# CC1350F128 register map
File version: 1.0
CPU: CM3 1.0, other endian, MPU, FPU, 3 interrupt priority bits
Registers are 32-bit, read-write, reset 0x0 unless marked. A register's access mark holds for its fields unless they carry their own. Offsets are from the block's base; [hi:lo] are bit positions; {n}, {i} and the like mark numbered series; 'fields as' and 'values as' point back to an identical list.

## FCFG1 — Factory configuration area (FCFG1)
Base 0x50001000
0xA0 MISC_CONF_1 reset 0xFFFFFF00 — Misc configurations
  [7:0] DEVICE_MINOR_REV ro — [7:0] HW minor revision number (a value of 0xFF shall be treated equally to 0x00). Any test of this field by SW should be implemented as a 'greater or equal' comparison as signed integer. Value may change without warning.
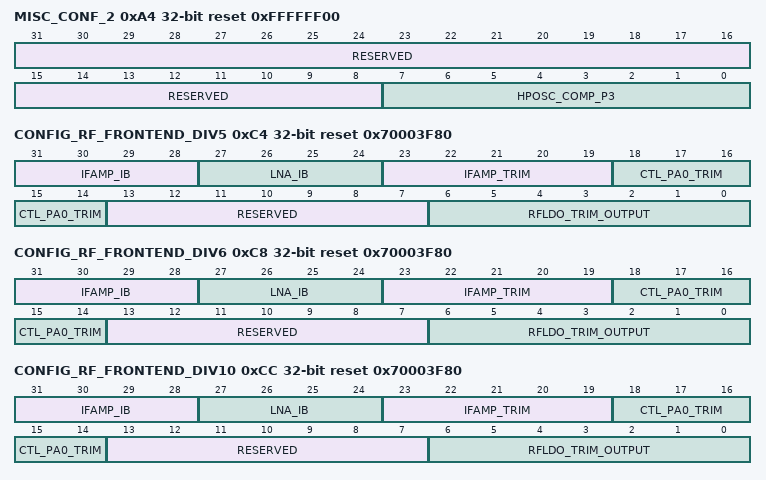
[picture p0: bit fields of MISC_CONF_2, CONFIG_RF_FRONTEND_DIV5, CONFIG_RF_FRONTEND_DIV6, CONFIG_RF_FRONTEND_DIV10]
0xA4 MISC_CONF_2 reset 0xFFFFFF00 — Internal. Only to be used through TI provided API.
  [31:8] RESERVED ro — [31:8] Internal. Only to be used through TI provided API.
  [7:0] HPOSC_COMP_P3 ro — [7:0] Internal. Only to be used through TI provided API.
0xC4 CONFIG_RF_FRONTEND_DIV5 reset 0x70003F80 — Internal. Only to be used through TI provided API.
  [31:28] IFAMP_IB ro — [31:28] Internal. Only to be used through TI provided API.
  [27:24] LNA_IB ro — [27:24] Internal. Only to be used through TI provided API.
  [23:19] IFAMP_TRIM ro — [23:19] Internal. Only to be used through TI provided API.
  [18:14] CTL_PA0_TRIM ro — [18:14] Internal. Only to be used through TI provided API.
  [13:7] RESERVED ro — [13:7] Internal. Only to be used through TI provided API.
  [6:0] RFLDO_TRIM_OUTPUT ro — [6:0] Internal. Only to be used through TI provided API.
0xC8 CONFIG_RF_FRONTEND_DIV6 reset 0x70003F80 — Internal. Only to be used through TI provided API.
  fields as CONFIG_RF_FRONTEND_DIV5
0xCC CONFIG_RF_FRONTEND_DIV10 reset 0x70003F80 — Internal. Only to be used through TI provided API.
  fields as CONFIG_RF_FRONTEND_DIV5
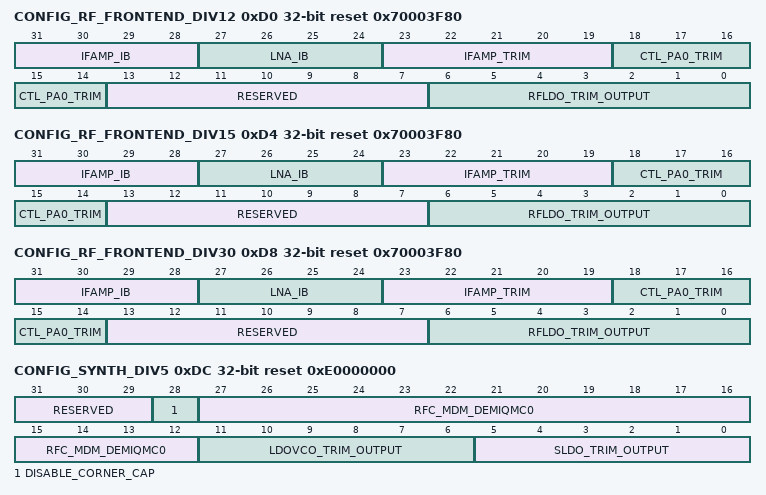
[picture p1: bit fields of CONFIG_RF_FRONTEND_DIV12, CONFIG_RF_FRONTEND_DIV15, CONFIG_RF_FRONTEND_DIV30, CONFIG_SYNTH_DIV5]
0xD0 CONFIG_RF_FRONTEND_DIV12 reset 0x70003F80 — Internal. Only to be used through TI provided API.
  fields as CONFIG_RF_FRONTEND_DIV5
0xD4 CONFIG_RF_FRONTEND_DIV15 reset 0x70003F80 — Internal. Only to be used through TI provided API.
  fields as CONFIG_RF_FRONTEND_DIV5
0xD8 CONFIG_RF_FRONTEND_DIV30 reset 0x70003F80 — Internal. Only to be used through TI provided API.
  fields as CONFIG_RF_FRONTEND_DIV5
0xDC CONFIG_SYNTH_DIV5 reset 0xE0000000 — Internal. Only to be used through TI provided API.
  [31:29] RESERVED ro — [31:29] Internal. Only to be used through TI provided API.
  [28] DISABLE_CORNER_CAP ro — [28:28] Internal. Only to be used through TI provided API.
  [27:12] RFC_MDM_DEMIQMC0 ro — [27:12] Trim value for RF Core. Value is read by RF Core ROM FW during RF Core initialization.
  [11:6] LDOVCO_TRIM_OUTPUT ro — [11:6] Internal. Only to be used through TI provided API.
  [5:0] SLDO_TRIM_OUTPUT ro — [5:0] Internal. Only to be used through TI provided API.
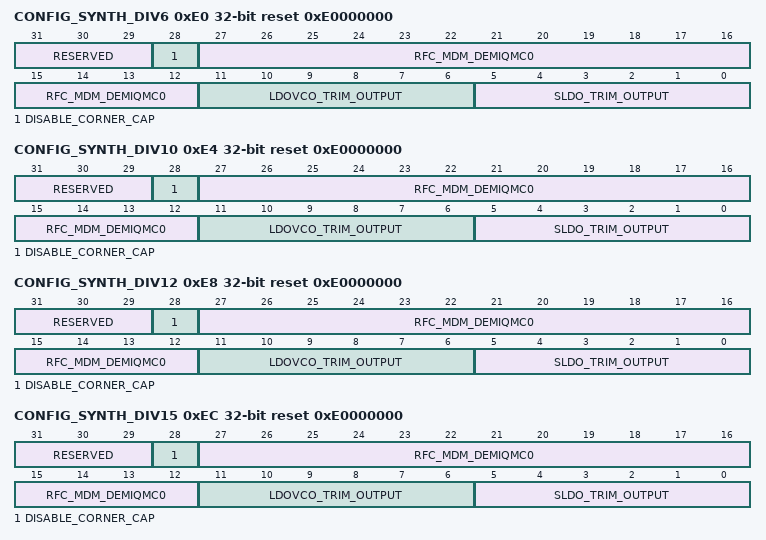
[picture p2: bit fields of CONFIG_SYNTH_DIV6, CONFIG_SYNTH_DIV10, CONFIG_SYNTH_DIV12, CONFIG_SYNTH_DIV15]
0xE0 CONFIG_SYNTH_DIV6 reset 0xE0000000 — Internal. Only to be used through TI provided API.
  fields as CONFIG_SYNTH_DIV5
0xE4 CONFIG_SYNTH_DIV10 reset 0xE0000000 — Internal. Only to be used through TI provided API.
  fields as CONFIG_SYNTH_DIV5
0xE8 CONFIG_SYNTH_DIV12 reset 0xE0000000 — Internal. Only to be used through TI provided API.
  fields as CONFIG_SYNTH_DIV5
0xEC CONFIG_SYNTH_DIV15 reset 0xE0000000 — Internal. Only to be used through TI provided API.
  fields as CONFIG_SYNTH_DIV5
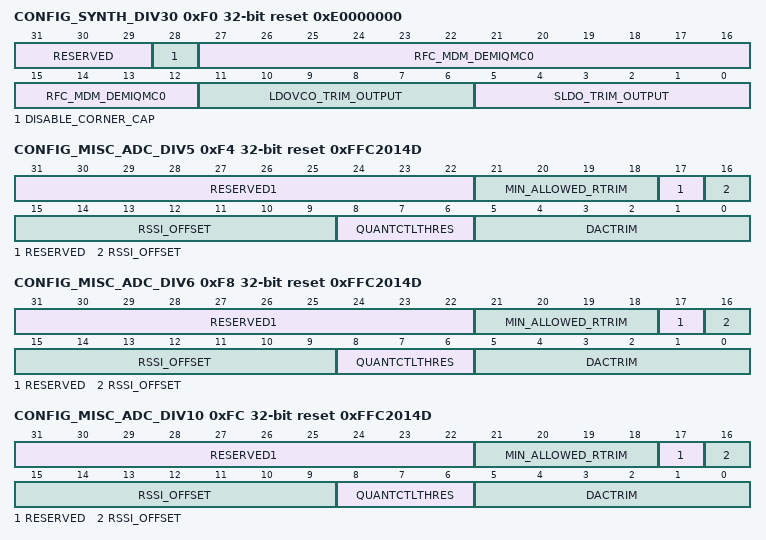
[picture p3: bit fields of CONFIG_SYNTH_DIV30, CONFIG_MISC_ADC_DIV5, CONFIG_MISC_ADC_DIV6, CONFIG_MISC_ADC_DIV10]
0xF0 CONFIG_SYNTH_DIV30 reset 0xE0000000 — Internal. Only to be used through TI provided API.
  fields as CONFIG_SYNTH_DIV5
0xF4 CONFIG_MISC_ADC_DIV5 reset 0xFFC2014D — Internal. Only to be used through TI provided API.
  [31:22] RESERVED1 ro — [31:22] Internal. Only to be used through TI provided API.
  [21:18] MIN_ALLOWED_RTRIM ro — [21:18] Internal. Only to be used through TI provided API.
  [17] RESERVED ro — [17:17] Internal. Only to be used through TI provided API.
  [16:9] RSSI_OFFSET ro — [16:9] Internal. Only to be used through TI provided API.
  [8:6] QUANTCTLTHRES ro — [8:6] Internal. Only to be used through TI provided API.
  [5:0] DACTRIM ro — [5:0] Internal. Only to be used through TI provided API.
0xF8 CONFIG_MISC_ADC_DIV6 reset 0xFFC2014D — Internal. Only to be used through TI provided API.
  fields as CONFIG_MISC_ADC_DIV5
0xFC CONFIG_MISC_ADC_DIV10 reset 0xFFC2014D — Internal. Only to be used through TI provided API.
  fields as CONFIG_MISC_ADC_DIV5
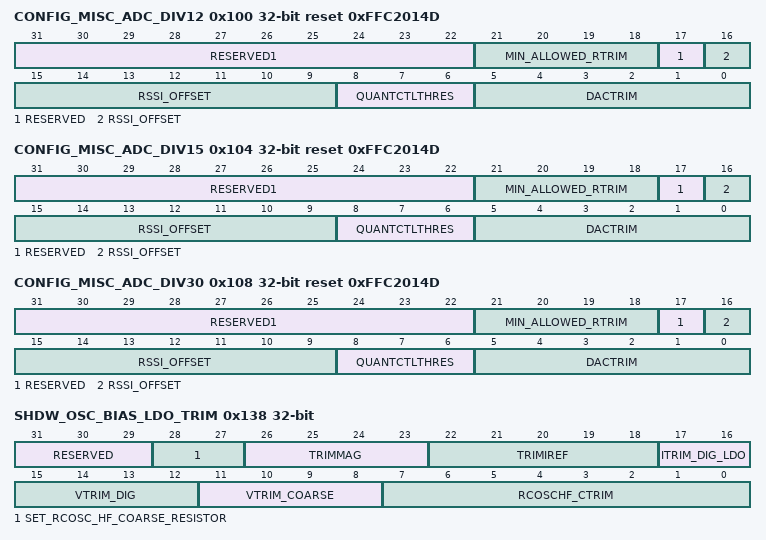
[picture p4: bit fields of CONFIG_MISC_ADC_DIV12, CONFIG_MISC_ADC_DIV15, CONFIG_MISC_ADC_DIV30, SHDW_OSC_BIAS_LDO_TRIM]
0x100 CONFIG_MISC_ADC_DIV12 reset 0xFFC2014D — Internal. Only to be used through TI provided API.
  fields as CONFIG_MISC_ADC_DIV5
0x104 CONFIG_MISC_ADC_DIV15 reset 0xFFC2014D — Internal. Only to be used through TI provided API.
  fields as CONFIG_MISC_ADC_DIV5
0x108 CONFIG_MISC_ADC_DIV30 reset 0xFFC2014D — Internal. Only to be used through TI provided API.
  fields as CONFIG_MISC_ADC_DIV5
{0x118+4i} SHDW_DIE_ID_{i} (i=0..3) — Shadow of the DIE_ID_{i} register in eFuse
  [31:0] ID_{32i+31}_{32i} ro — [31:0] Shadow of the DIE_ID_{i} register in eFuse row number {i+3}
0x138 SHDW_OSC_BIAS_LDO_TRIM — Internal. Only to be used through TI provided API.
  [31:29] RESERVED ro — [31:29] Internal. Only to be used through TI provided API.
  [28:27] SET_RCOSC_HF_COARSE_RESISTOR ro — [28:27] Internal. Only to be used through TI provided API.
  [26:23] TRIMMAG ro — [26:23] Internal. Only to be used through TI provided API.
  [22:18] TRIMIREF ro — [22:18] Internal. Only to be used through TI provided API.
  [17:16] ITRIM_DIG_LDO ro — [17:16] Internal. Only to be used through TI provided API.
  [15:12] VTRIM_DIG ro — [15:12] Internal. Only to be used through TI provided API.
  [11:8] VTRIM_COARSE ro — [11:8] Internal. Only to be used through TI provided API.
  [7:0] RCOSCHF_CTRIM ro — [7:0] Internal. Only to be used through TI provided API.
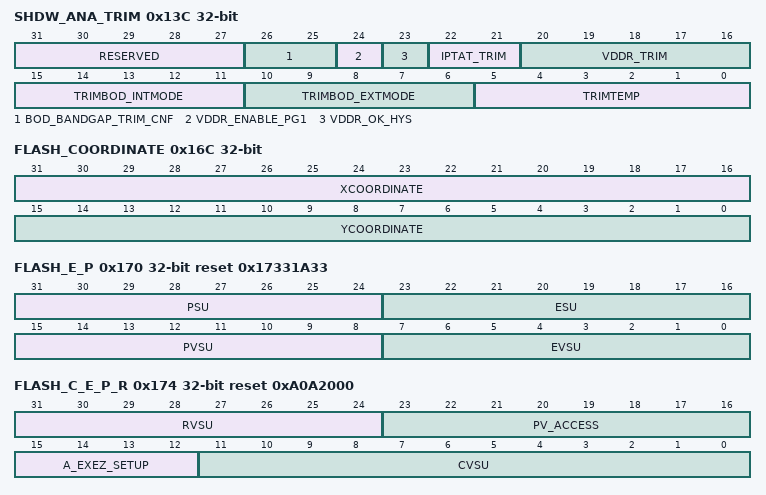
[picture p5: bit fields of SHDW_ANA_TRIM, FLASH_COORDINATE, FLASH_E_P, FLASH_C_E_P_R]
0x13C SHDW_ANA_TRIM — Internal. Only to be used through TI provided API.
  [31:27] RESERVED ro — [31:27] Internal. Only to be used through TI provided API.
  [26:25] BOD_BANDGAP_TRIM_CNF ro — [26:25] Internal. Only to be used through TI provided API.
  [24] VDDR_ENABLE_PG1 ro — [24:24] Internal. Only to be used through TI provided API.
  [23] VDDR_OK_HYS ro — [23:23] Internal. Only to be used through TI provided API.
  [22:21] IPTAT_TRIM ro — [22:21] Internal. Only to be used through TI provided API.
  [20:16] VDDR_TRIM ro — [20:16] Internal. Only to be used through TI provided API.
  [15:11] TRIMBOD_INTMODE ro — [15:11] Internal. Only to be used through TI provided API.
  [10:6] TRIMBOD_EXTMODE ro — [10:6] Internal. Only to be used through TI provided API.
  [5:0] TRIMTEMP ro — [5:0] Internal. Only to be used through TI provided API.
0x164 FLASH_NUMBER
  [31:0] LOT_NUMBER ro — [31:0] Number of the manufacturing lot that produced this unit.
0x16C FLASH_COORDINATE
  [31:16] XCOORDINATE ro — [31:16] X coordinate of this unit on the wafer.
  [15:0] YCOORDINATE ro — [15:0] Y coordinate of this unit on the wafer.
0x170 FLASH_E_P reset 0x17331A33 — Internal. Only to be used through TI provided API.
  [31:24] PSU ro — [31:24] Internal. Only to be used through TI provided API.
  [23:16] ESU ro — [23:16] Internal. Only to be used through TI provided API.
  [15:8] PVSU ro — [15:8] Internal. Only to be used through TI provided API.
  [7:0] EVSU ro — [7:0] Internal. Only to be used through TI provided API.
0x174 FLASH_C_E_P_R reset 0xA0A2000 — Internal. Only to be used through TI provided API.
  [31:24] RVSU ro — [31:24] Internal. Only to be used through TI provided API.
  [23:16] PV_ACCESS ro — [23:16] Internal. Only to be used through TI provided API.
  [15:12] A_EXEZ_SETUP ro — [15:12] Internal. Only to be used through TI provided API.
  [11:0] CVSU ro — [11:0] Internal. Only to be used through TI provided API.
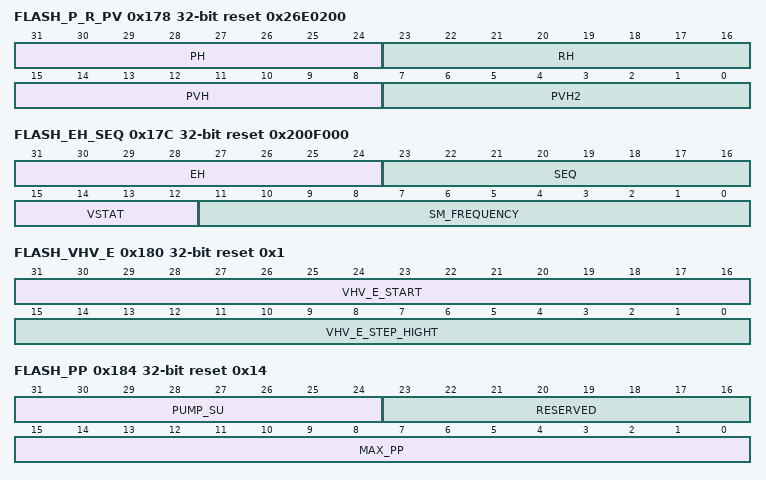
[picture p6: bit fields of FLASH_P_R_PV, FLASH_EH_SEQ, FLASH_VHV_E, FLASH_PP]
0x178 FLASH_P_R_PV reset 0x26E0200 — Internal. Only to be used through TI provided API.
  [31:24] PH ro — [31:24] Internal. Only to be used through TI provided API.
  [23:16] RH ro — [23:16] Internal. Only to be used through TI provided API.
  [15:8] PVH ro — [15:8] Internal. Only to be used through TI provided API.
  [7:0] PVH2 ro — [7:0] Internal. Only to be used through TI provided API.
0x17C FLASH_EH_SEQ reset 0x200F000 — Internal. Only to be used through TI provided API.
  [31:24] EH ro — [31:24] Internal. Only to be used through TI provided API.
  [23:16] SEQ ro — [23:16] Internal. Only to be used through TI provided API.
  [15:12] VSTAT ro — [15:12] Internal. Only to be used through TI provided API.
  [11:0] SM_FREQUENCY ro — [11:0] Internal. Only to be used through TI provided API.
0x180 FLASH_VHV_E reset 0x1 — Internal. Only to be used through TI provided API.
  [31:16] VHV_E_START ro — [31:16] Internal. Only to be used through TI provided API.
  [15:0] VHV_E_STEP_HIGHT ro — [15:0] Internal. Only to be used through TI provided API.
0x184 FLASH_PP reset 0x14 — Internal. Only to be used through TI provided API.
  [31:24] PUMP_SU ro — [31:24] Internal. Only to be used through TI provided API.
  [23:16] RESERVED ro — [23:16] Internal. Only to be used through TI provided API.
  [15:0] MAX_PP ro — [15:0] Internal. Only to be used through TI provided API.
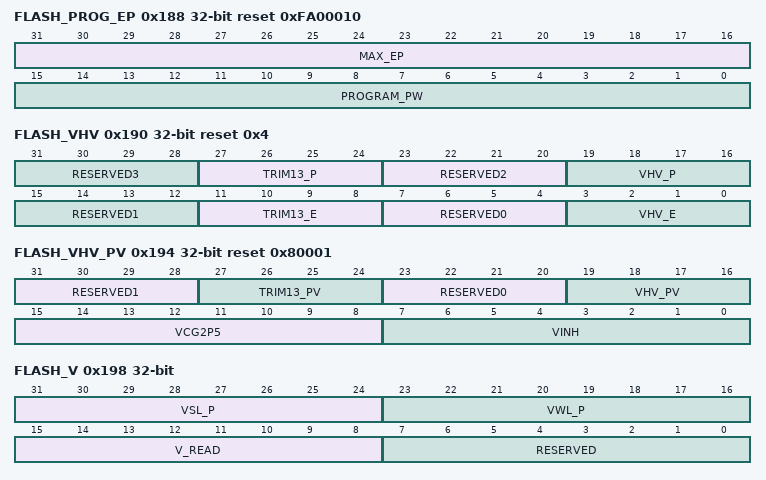
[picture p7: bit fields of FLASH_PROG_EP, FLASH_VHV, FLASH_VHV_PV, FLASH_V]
0x188 FLASH_PROG_EP reset 0xFA00010 — Internal. Only to be used through TI provided API.
  [31:16] MAX_EP ro — [31:16] Internal. Only to be used through TI provided API.
  [15:0] PROGRAM_PW ro — [15:0] Internal. Only to be used through TI provided API.
0x18C FLASH_ERA_PW reset 0xFA0 — Internal. Only to be used through TI provided API.
  [31:0] ERASE_PW ro — [31:0] Internal. Only to be used through TI provided API.
0x190 FLASH_VHV reset 0x4 — Internal. Only to be used through TI provided API.
  [8n+7:8n+4] RESERVED{n} ro (n=0..3) — [{8n+7}:{8n+4}] Internal. Only to be used through TI provided API.
  [27:24] TRIM13_P ro — [27:24] Internal. Only to be used through TI provided API.
  [19:16] VHV_P ro — [19:16] Internal. Only to be used through TI provided API.
  [11:8] TRIM13_E ro — [11:8] Internal. Only to be used through TI provided API.
  [3:0] VHV_E ro — [3:0] Internal. Only to be used through TI provided API.
0x194 FLASH_VHV_PV reset 0x80001 — Internal. Only to be used through TI provided API.
  [31:28] RESERVED1 ro — [31:28] Internal. Only to be used through TI provided API.
  [27:24] TRIM13_PV ro — [27:24] Internal. Only to be used through TI provided API.
  [23:20] RESERVED0 ro — [23:20] Internal. Only to be used through TI provided API.
  [19:16] VHV_PV ro — [19:16] Internal. Only to be used through TI provided API.
  [15:8] VCG2P5 ro — [15:8] Internal. Only to be used through TI provided API.
  [7:0] VINH ro — [7:0] Internal. Only to be used through TI provided API.
0x198 FLASH_V — Internal. Only to be used through TI provided API.
  [31:24] VSL_P ro — [31:24] Internal. Only to be used through TI provided API.
  [23:16] VWL_P ro — [23:16] Internal. Only to be used through TI provided API.
  [15:8] V_READ ro — [15:8] Internal. Only to be used through TI provided API.
  [7:0] RESERVED ro — [7:0] Internal. Only to be used through TI provided API.
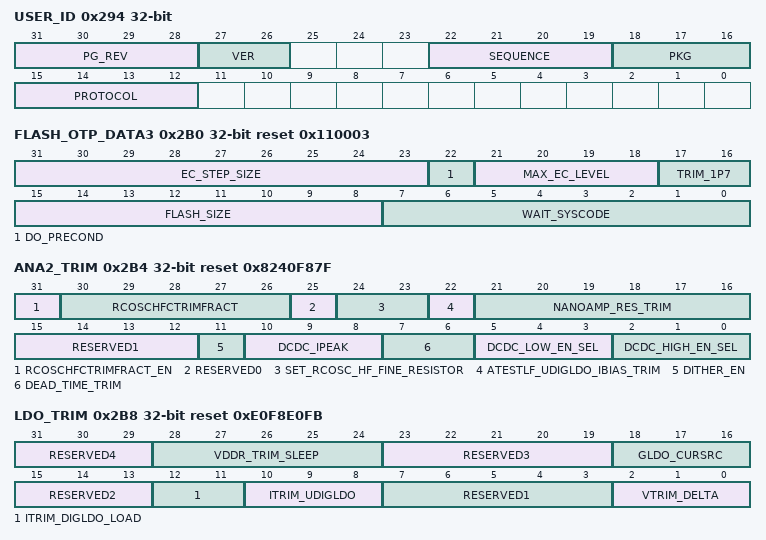
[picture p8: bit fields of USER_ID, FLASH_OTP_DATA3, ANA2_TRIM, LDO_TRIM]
0x294 USER_ID — User Identification. Reading this register and the ICEPICK_DEVICE_ID register is the only support way of identifying a device. The value of this register will be written to AON_WUC:JTAGUSERCODE by boot FW while in safezone.
  [31:28] PG_REV ro — [31:28] Field used to distinguish revisions of the device.
  [27:26] VER ro — [27:26] Version number. 0x0: Bits [25:12] of this register has the stated meaning. Any other setting indicate a different encoding of these bits.
  [22:19] SEQUENCE ro — [22:19] Sequence. Used to differentiate between marketing/orderable product where other fields of USER_ID is the same (temp range, flash size, voltage range etc)
  [18:16] PKG ro — [18:16] Package type. 0x0: 4x4mm QFN (RHB) package 0x1: 5x5mm QFN (RSM) package 0x2: 7x7mm QFN (RGZ) package 0x3: Wafer sale package (naked die) 0x4: 2.7x2.7mm WCSP (YFV) 0x5: 7x7mm QFN package with Wettable Flanks Other values are reserved for future use. Packages available for a specific device are shown in the device datasheet.
  [15:12] PROTOCOL ro — [15:12] Protocols supported. 0x1: BLE 0x2: RF4CE 0x4: Zigbee/6lowpan 0x8: Proprietary More than one protocol can be supported on same device - values above are then combined.
0x2B0 FLASH_OTP_DATA3 reset 0x110003 — Internal. Only to be used through TI provided API.
  [31:23] EC_STEP_SIZE ro — [31:23] Internal. Only to be used through TI provided API.
  [22] DO_PRECOND ro — [22:22] Internal. Only to be used through TI provided API.
  [21:18] MAX_EC_LEVEL ro — [21:18] Internal. Only to be used through TI provided API.
  [17:16] TRIM_1P7 ro — [17:16] Internal. Only to be used through TI provided API.
  [15:8] FLASH_SIZE ro — [15:8] Internal. Only to be used through TI provided API.
  [7:0] WAIT_SYSCODE ro — [7:0] Internal. Only to be used through TI provided API.
0x2B4 ANA2_TRIM reset 0x8240F87F — Internal. Only to be used through TI provided API.
  [31] RCOSCHFCTRIMFRACT_EN ro — [31:31] Internal. Only to be used through TI provided API.
  [30:26] RCOSCHFCTRIMFRACT ro — [30:26] Internal. Only to be used through TI provided API.
  [25] RESERVED0 ro — [25:25] Internal. Only to be used through TI provided API.
  [24:23] SET_RCOSC_HF_FINE_RESISTOR ro — [24:23] Internal. Only to be used through TI provided API.
  [22] ATESTLF_UDIGLDO_IBIAS_TRIM ro — [22:22] Internal. Only to be used through TI provided API.
  [21:16] NANOAMP_RES_TRIM ro — [21:16] Internal. Only to be used through TI provided API.
  [15:12] RESERVED1 ro — [15:12] Internal. Only to be used through TI provided API.
  [11] DITHER_EN ro — [11:11] Internal. Only to be used through TI provided API.
  [10:8] DCDC_IPEAK ro — [10:8] Internal. Only to be used through TI provided API.
  [7:6] DEAD_TIME_TRIM ro — [7:6] Internal. Only to be used through TI provided API.
  [5:3] DCDC_LOW_EN_SEL ro — [5:3] Internal. Only to be used through TI provided API.
  [2:0] DCDC_HIGH_EN_SEL ro — [2:0] Internal. Only to be used through TI provided API.
0x2B8 LDO_TRIM reset 0xE0F8E0FB — Internal. Only to be used through TI provided API.
  [31:29] RESERVED4 ro — [31:29] Internal. Only to be used through TI provided API.
  [28:24] VDDR_TRIM_SLEEP ro — [28:24] Internal. Only to be used through TI provided API.
  [23:19] RESERVED3 ro — [23:19] Internal. Only to be used through TI provided API.
  [18:16] GLDO_CURSRC ro — [18:16] Internal. Only to be used through TI provided API.
  [15:13] RESERVED2 ro — [15:13] Internal. Only to be used through TI provided API.
  [12:11] ITRIM_DIGLDO_LOAD ro — [12:11] Internal. Only to be used through TI provided API.
  [10:8] ITRIM_UDIGLDO ro — [10:8] Internal. Only to be used through TI provided API.
  [7:3] RESERVED1 ro — [7:3] Internal. Only to be used through TI provided API.
  [2:0] VTRIM_DELTA ro — [2:0] Internal. Only to be used through TI provided API.
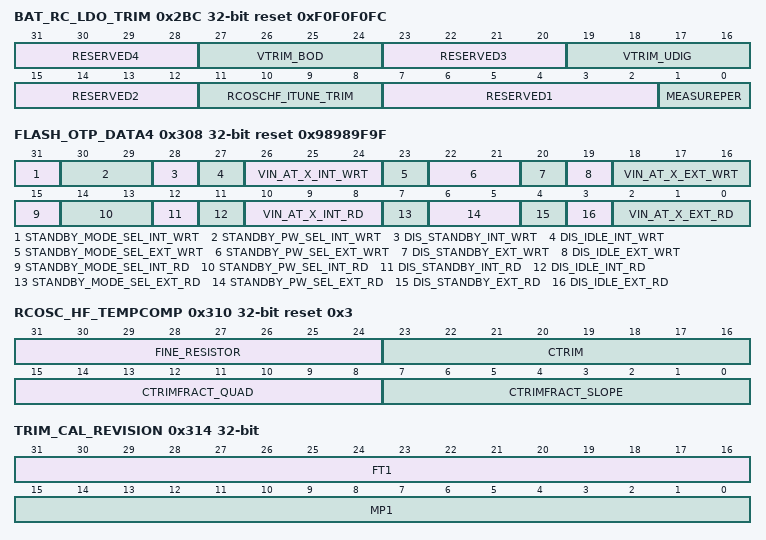
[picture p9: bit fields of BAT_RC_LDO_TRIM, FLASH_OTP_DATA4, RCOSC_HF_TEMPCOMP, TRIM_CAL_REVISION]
0x2BC BAT_RC_LDO_TRIM reset 0xF0F0F0FC — Internal. Only to be used through TI provided API.
  [31:28] RESERVED4 ro — [31:28] Internal. Only to be used through TI provided API.
  [27:24] VTRIM_BOD ro — [27:24] Internal. Only to be used through TI provided API.
  [23:20] RESERVED3 ro — [23:20] Internal. Only to be used through TI provided API.
  [19:16] VTRIM_UDIG ro — [19:16] Internal. Only to be used through TI provided API.
  [15:12] RESERVED2 ro — [15:12] Internal. Only to be used through TI provided API.
  [11:8] RCOSCHF_ITUNE_TRIM ro — [11:8] Internal. Only to be used through TI provided API.
  [7:2] RESERVED1 ro — [7:2] Internal. Only to be used through TI provided API.
  [1:0] MEASUREPER ro — [1:0] Internal. Only to be used through TI provided API.
0x2E8 MAC_BLE_0 — MAC BLE Address 0
  [31:0] ADDR_0_31 ro — [31:0] The first 32-bits of the 64-bit MAC BLE address
0x2EC MAC_BLE_1 — MAC BLE Address 1
  [31:0] ADDR_32_63 ro — [31:0] The last 32-bits of the 64-bit MAC BLE address
0x2F0 MAC_15_4_0 — MAC IEEE 802.15.4 Address 0
  [31:0] ADDR_0_31 ro — [31:0] The first 32-bits of the 64-bit MAC 15.4 address
0x2F4 MAC_15_4_1 — MAC IEEE 802.15.4 Address 1
  [31:0] ADDR_32_63 ro — [31:0] The last 32-bits of the 64-bit MAC 15.4 address
0x308 FLASH_OTP_DATA4 reset 0x98989F9F — Internal. Only to be used through TI provided API.
  [31] STANDBY_MODE_SEL_INT_WRT ro — [31:31] Internal. Only to be used through TI provided API.
  [30:29] STANDBY_PW_SEL_INT_WRT ro — [30:29] Internal. Only to be used through TI provided API.
  [28] DIS_STANDBY_INT_WRT ro — [28:28] Internal. Only to be used through TI provided API.
  [27] DIS_IDLE_INT_WRT ro — [27:27] Internal. Only to be used through TI provided API.
  [26:24] VIN_AT_X_INT_WRT ro — [26:24] Internal. Only to be used through TI provided API.
  [23] STANDBY_MODE_SEL_EXT_WRT ro — [23:23] Internal. Only to be used through TI provided API.
  [22:21] STANDBY_PW_SEL_EXT_WRT ro — [22:21] Internal. Only to be used through TI provided API.
  [20] DIS_STANDBY_EXT_WRT ro — [20:20] Internal. Only to be used through TI provided API.
  [19] DIS_IDLE_EXT_WRT ro — [19:19] Internal. Only to be used through TI provided API.
  [18:16] VIN_AT_X_EXT_WRT ro — [18:16] Internal. Only to be used through TI provided API.
  [15] STANDBY_MODE_SEL_INT_RD ro — [15:15] Internal. Only to be used through TI provided API.
  [14:13] STANDBY_PW_SEL_INT_RD ro — [14:13] Internal. Only to be used through TI provided API.
  [12] DIS_STANDBY_INT_RD ro — [12:12] Internal. Only to be used through TI provided API.
  [11] DIS_IDLE_INT_RD ro — [11:11] Internal. Only to be used through TI provided API.
  [10:8] VIN_AT_X_INT_RD ro — [10:8] Internal. Only to be used through TI provided API.
  [7] STANDBY_MODE_SEL_EXT_RD ro — [7:7] Internal. Only to be used through TI provided API.
  [6:5] STANDBY_PW_SEL_EXT_RD ro — [6:5] Internal. Only to be used through TI provided API.
  [4] DIS_STANDBY_EXT_RD ro — [4:4] Internal. Only to be used through TI provided API.
  [3] DIS_IDLE_EXT_RD ro — [3:3] Internal. Only to be used through TI provided API.
  [2:0] VIN_AT_X_EXT_RD ro — [2:0] Internal. Only to be used through TI provided API.
0x30C MISC_TRIM reset 0xFFFFFF33 — Miscellaneous Trim Parameters
  [7:0] TEMPVSLOPE ro — [7:0] Signed byte value representing the TEMP slope with battery voltage, in degrees C / V, with four fractional bits.
0x310 RCOSC_HF_TEMPCOMP reset 0x3 — Internal. Only to be used through TI provided API.
  [31:24] FINE_RESISTOR ro — [31:24] Internal. Only to be used through TI provided API.
  [23:16] CTRIM ro — [23:16] Internal. Only to be used through TI provided API.
  [15:8] CTRIMFRACT_QUAD ro — [15:8] Internal. Only to be used through TI provided API.
  [7:0] CTRIMFRACT_SLOPE ro — [7:0] Internal. Only to be used through TI provided API.
0x314 TRIM_CAL_REVISION — Internal. Only to be used through TI provided API.
  [31:16] FT1 ro — [31:16] Internal. Only to be used through TI provided API.
  [15:0] MP1 ro — [15:0] Internal. Only to be used through TI provided API.
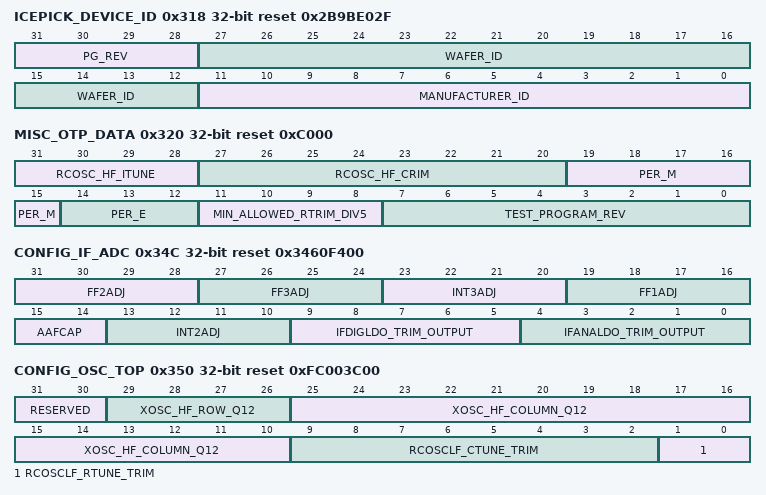
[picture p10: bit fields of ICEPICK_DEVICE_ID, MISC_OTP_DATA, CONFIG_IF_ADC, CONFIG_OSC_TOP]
0x318 ICEPICK_DEVICE_ID reset 0x2B9BE02F — IcePick Device Identification Reading this register and the USER_ID register is the only support way of identifying a device.
  [31:28] PG_REV ro — [31:28] Field used to distinguish revisions of the device.
  [27:12] WAFER_ID ro — [27:12] Field used to identify silicon die.
  [11:0] MANUFACTURER_ID ro — [11:0] Manufacturer code. 0x02F: Texas Instruments
0x31C FCFG1_REVISION reset 0x26 — Factory Configuration (FCFG1) Revision
  [31:0] REV ro — [31:0] The revision number of the FCFG1 layout. This value will be read by application SW in order to determine which FCFG1 parameters that have valid values. This revision number must be incremented by 1 before any devices are to be produced if the FCFG1 layout has changed since the previous production of devices. Value migth change without warning.
0x320 MISC_OTP_DATA reset 0xC000
  [31:28] RCOSC_HF_ITUNE ro — [31:28] Internal. Only to be used through TI provided API.
  [27:20] RCOSC_HF_CRIM ro — [27:20] Internal. Only to be used through TI provided API.
  [19:15] PER_M ro — [19:15] Internal. Only to be used through TI provided API.
  [14:12] PER_E ro — [14:12] Internal. Only to be used through TI provided API.
  [11:8] MIN_ALLOWED_RTRIM_DIV5 ro — [11:8] Internal. Only to be used through TI provided API.
  [7:0] TEST_PROGRAM_REV ro — [7:0] The revision of the test program used in the production process when FCFG1 was programmed. Value migth change without warning.
0x344 IOCONF reset 0xFFFFFF00 — IO Configuration
  [6:0] GPIO_CNT ro — [6:0] Number of available DIOs.
0x34C CONFIG_IF_ADC reset 0x3460F400 — Internal. Only to be used through TI provided API.
  [31:28] FF2ADJ ro — [31:28] Internal. Only to be used through TI provided API.
  [27:24] FF3ADJ ro — [27:24] Internal. Only to be used through TI provided API.
  [23:20] INT3ADJ ro — [23:20] Internal. Only to be used through TI provided API.
  [19:16] FF1ADJ ro — [19:16] Internal. Only to be used through TI provided API.
  [15:14] AAFCAP ro — [15:14] Internal. Only to be used through TI provided API.
  [13:10] INT2ADJ ro — [13:10] Internal. Only to be used through TI provided API.
  [9:5] IFDIGLDO_TRIM_OUTPUT ro — [9:5] Internal. Only to be used through TI provided API.
  [4:0] IFANALDO_TRIM_OUTPUT ro — [4:0] Internal. Only to be used through TI provided API.
0x350 CONFIG_OSC_TOP reset 0xFC003C00 — Internal. Only to be used through TI provided API.
  [31:30] RESERVED ro — [31:30] Internal. Only to be used through TI provided API.
  [29:26] XOSC_HF_ROW_Q12 ro — [29:26] Internal. Only to be used through TI provided API.
  [25:10] XOSC_HF_COLUMN_Q12 ro — [25:10] Internal. Only to be used through TI provided API.
  [9:2] RCOSCLF_CTUNE_TRIM ro — [9:2] Internal. Only to be used through TI provided API.
  [1:0] RCOSCLF_RTUNE_TRIM ro — [1:0] Internal. Only to be used through TI provided API.
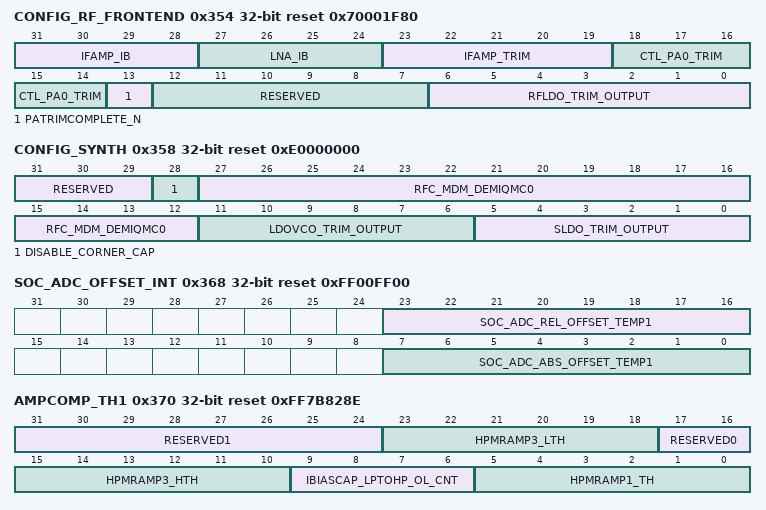
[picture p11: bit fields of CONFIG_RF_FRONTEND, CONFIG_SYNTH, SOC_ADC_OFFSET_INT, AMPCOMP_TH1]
0x354 CONFIG_RF_FRONTEND reset 0x70001F80 — Internal. Only to be used through TI provided API.
  [31:28] IFAMP_IB ro — [31:28] Internal. Only to be used through TI provided API.
  [27:24] LNA_IB ro — [27:24] Internal. Only to be used through TI provided API.
  [23:19] IFAMP_TRIM ro — [23:19] Internal. Only to be used through TI provided API.
  [18:14] CTL_PA0_TRIM ro — [18:14] Internal. Only to be used through TI provided API.
  [13] PATRIMCOMPLETE_N ro — [13:13] Internal. Only to be used through TI provided API.
  [12:7] RESERVED ro — [12:7] Internal. Only to be used through TI provided API.
  [6:0] RFLDO_TRIM_OUTPUT ro — [6:0] Internal. Only to be used through TI provided API.
0x358 CONFIG_SYNTH reset 0xE0000000 — Internal. Only to be used through TI provided API.
  [31:29] RESERVED ro — [31:29] Internal. Only to be used through TI provided API.
  [28] DISABLE_CORNER_CAP ro — [28:28] Internal. Only to be used through TI provided API.
  [27:12] RFC_MDM_DEMIQMC0 ro — [27:12] Trim value for RF Core. Value is read by RF Core ROM FW during RF Core initialization only on cc13x0.
  [11:6] LDOVCO_TRIM_OUTPUT ro — [11:6] Internal. Only to be used through TI provided API.
  [5:0] SLDO_TRIM_OUTPUT ro — [5:0] Internal. Only to be used through TI provided API.
0x35C SOC_ADC_ABS_GAIN reset 0xFFFF0000 — AUX_ADC Gain in Absolute Reference Mode
  [15:0] SOC_ADC_ABS_GAIN_TEMP1 ro — [15:0] SOC_ADC gain in absolute reference mode at temperature 1 (30C). Calculated in production test..
0x360 SOC_ADC_REL_GAIN reset 0xFFFF0000 — AUX_ADC Gain in Relative Reference Mode
  [15:0] SOC_ADC_REL_GAIN_TEMP1 ro — [15:0] SOC_ADC gain in relative reference mode at temperature 1 (30C). Calculated in production test..
0x368 SOC_ADC_OFFSET_INT reset 0xFF00FF00 — AUX_ADC Temperature Offsets in Absolute Reference Mode
  [23:16] SOC_ADC_REL_OFFSET_TEMP1 ro — [23:16] SOC_ADC offset in relative reference mode at temperature 1 (30C). Signed 8-bit number. Calculated in production test..
  [7:0] SOC_ADC_ABS_OFFSET_TEMP1 ro — [7:0] SOC_ADC offset in absolute reference mode at temperature 1 (30C). Signed 8-bit number. Calculated in production test..
0x36C SOC_ADC_REF_TRIM_AND_OFFSET_EXT reset 0xFFFFFF80 — Internal. Only to be used through TI provided API.
  [5:0] SOC_ADC_REF_VOLTAGE_TRIM_TEMP1 ro — [5:0] Internal. Only to be used through TI provided API.
0x370 AMPCOMP_TH1 reset 0xFF7B828E — Internal. Only to be used through TI provided API.
  [31:24] RESERVED1 ro — [31:24] Internal. Only to be used through TI provided API.
  [23:18] HPMRAMP3_LTH ro — [23:18] Internal. Only to be used through TI provided API.
  [17:16] RESERVED0 ro — [17:16] Internal. Only to be used through TI provided API.
  [15:10] HPMRAMP3_HTH ro — [15:10] Internal. Only to be used through TI provided API.
  [9:6] IBIASCAP_LPTOHP_OL_CNT ro — [9:6] Internal. Only to be used through TI provided API.
  [5:0] HPMRAMP1_TH ro — [5:0] Internal. Only to be used through TI provided API.
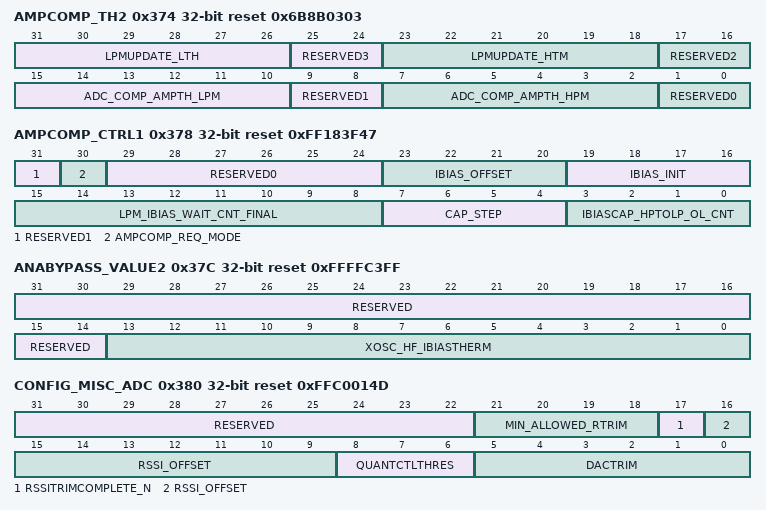
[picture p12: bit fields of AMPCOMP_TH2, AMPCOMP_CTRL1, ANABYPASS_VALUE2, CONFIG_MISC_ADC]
0x374 AMPCOMP_TH2 reset 0x6B8B0303 — Internal. Only to be used through TI provided API.
  [31:26] LPMUPDATE_LTH ro — [31:26] Internal. Only to be used through TI provided API.
  [8n+1:8n] RESERVED{n} ro (n=0..3) — [{8n+1}:{8n}] Internal. Only to be used through TI provided API.
  [23:18] LPMUPDATE_HTM ro — [23:18] Internal. Only to be used through TI provided API.
  [15:10] ADC_COMP_AMPTH_LPM ro — [15:10] Internal. Only to be used through TI provided API.
  [7:2] ADC_COMP_AMPTH_HPM ro — [7:2] Internal. Only to be used through TI provided API.
0x378 AMPCOMP_CTRL1 reset 0xFF183F47 — Internal. Only to be used through TI provided API.
  [31] RESERVED1 ro — [31:31] Internal. Only to be used through TI provided API.
  [30] AMPCOMP_REQ_MODE ro — [30:30] Internal. Only to be used through TI provided API.
  [29:24] RESERVED0 ro — [29:24] Internal. Only to be used through TI provided API.
  [23:20] IBIAS_OFFSET ro — [23:20] Internal. Only to be used through TI provided API.
  [19:16] IBIAS_INIT ro — [19:16] Internal. Only to be used through TI provided API.
  [15:8] LPM_IBIAS_WAIT_CNT_FINAL ro — [15:8] Internal. Only to be used through TI provided API.
  [7:4] CAP_STEP ro — [7:4] Internal. Only to be used through TI provided API.
  [3:0] IBIASCAP_HPTOLP_OL_CNT ro — [3:0] Internal. Only to be used through TI provided API.
0x37C ANABYPASS_VALUE2 reset 0xFFFFC3FF — Internal. Only to be used through TI provided API.
  [31:14] RESERVED ro — [31:14] Internal. Only to be used through TI provided API.
  [13:0] XOSC_HF_IBIASTHERM ro — [13:0] Internal. Only to be used through TI provided API.
0x380 CONFIG_MISC_ADC reset 0xFFC0014D — Internal. Only to be used through TI provided API.
  [31:22] RESERVED ro — [31:22] Internal. Only to be used through TI provided API.
  [21:18] MIN_ALLOWED_RTRIM ro — [21:18] Internal. Only to be used through TI provided API.
  [17] RSSITRIMCOMPLETE_N ro — [17:17] Internal. Only to be used through TI provided API.
  [16:9] RSSI_OFFSET ro — [16:9] Internal. Only to be used through TI provided API.
  [8:6] QUANTCTLTHRES ro — [8:6] Internal. Only to be used through TI provided API.
  [5:0] DACTRIM ro — [5:0] Internal. Only to be used through TI provided API.
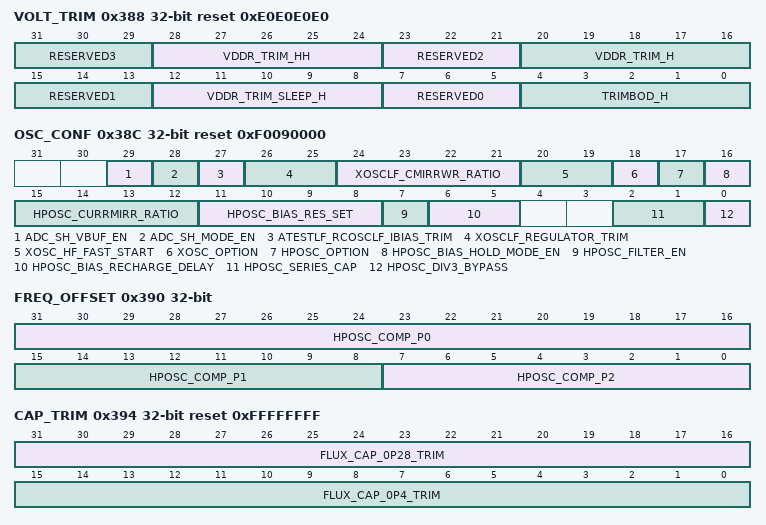
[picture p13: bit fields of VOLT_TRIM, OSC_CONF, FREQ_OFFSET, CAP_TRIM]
0x388 VOLT_TRIM reset 0xE0E0E0E0 — Internal. Only to be used through TI provided API.
  [8n+7:8n+5] RESERVED{n} ro (n=0..3) — [{8n+7}:{8n+5}] Internal. Only to be used through TI provided API.
  [28:24] VDDR_TRIM_HH ro — [28:24] Internal. Only to be used through TI provided API.
  [20:16] VDDR_TRIM_H ro — [20:16] Internal. Only to be used through TI provided API.
  [12:8] VDDR_TRIM_SLEEP_H ro — [12:8] Internal. Only to be used through TI provided API.
  [4:0] TRIMBOD_H ro — [4:0] Internal. Only to be used through TI provided API.
0x38C OSC_CONF reset 0xF0090000 — OSC Configuration
  [29] ADC_SH_VBUF_EN ro — [29:29] Trim value for DDI_0_OSC:ADCDOUBLERNANOAMPCTL.ADC_SH_VBUF_EN.
  [28] ADC_SH_MODE_EN ro — [28:28] Trim value for DDI_0_OSC:ADCDOUBLERNANOAMPCTL.ADC_SH_MODE_EN.
  [27] ATESTLF_RCOSCLF_IBIAS_TRIM ro — [27:27] Trim value for DDI_0_OSC:ATESTCTL.ATESTLF_RCOSCLF_IBIAS_TRIM.
  [26:25] XOSCLF_REGULATOR_TRIM ro — [26:25] Trim value for DDI_0_OSC:LFOSCCTL.XOSCLF_REGULATOR_TRIM.
  [24:21] XOSCLF_CMIRRWR_RATIO ro — [24:21] Trim value for DDI_0_OSC:LFOSCCTL.XOSCLF_CMIRRWR_RATIO.
  [20:19] XOSC_HF_FAST_START ro — [20:19] Trim value for DDI_0_OSC:CTL1.XOSC_HF_FAST_START.
  [18] XOSC_OPTION ro — [18:18] 0: XOSC_HF unavailable (may not be bonded out) 1: XOSC_HF available (default)
  [17] HPOSC_OPTION ro — [17:17] Internal. Only to be used through TI provided API.
  [16] HPOSC_BIAS_HOLD_MODE_EN ro — [16:16] Internal. Only to be used through TI provided API.
  [15:12] HPOSC_CURRMIRR_RATIO ro — [15:12] Internal. Only to be used through TI provided API.
  [11:8] HPOSC_BIAS_RES_SET ro — [11:8] Internal. Only to be used through TI provided API.
  [7] HPOSC_FILTER_EN ro — [7:7] Internal. Only to be used through TI provided API.
  [6:5] HPOSC_BIAS_RECHARGE_DELAY ro — [6:5] Internal. Only to be used through TI provided API.
  [2:1] HPOSC_SERIES_CAP ro — [2:1] Internal. Only to be used through TI provided API.
  [0] HPOSC_DIV3_BYPASS ro — [0:0] Internal. Only to be used through TI provided API.
0x390 FREQ_OFFSET — Internal. Only to be used through TI provided API.
  [31:16] HPOSC_COMP_P0 ro — [31:16] Internal. Only to be used through TI provided API.
  [15:8] HPOSC_COMP_P1 ro — [15:8] Internal. Only to be used through TI provided API.
  [7:0] HPOSC_COMP_P2 ro — [7:0] Internal. Only to be used through TI provided API.
0x394 CAP_TRIM reset 0xFFFFFFFF — Internal. Only to be used through TI provided API.
  [31:16] FLUX_CAP_0P28_TRIM ro — [31:16] Internal. Only to be used through TI provided API.
  [15:0] FLUX_CAP_0P4_TRIM ro — [15:0] Internal. Only to be used through TI provided API.
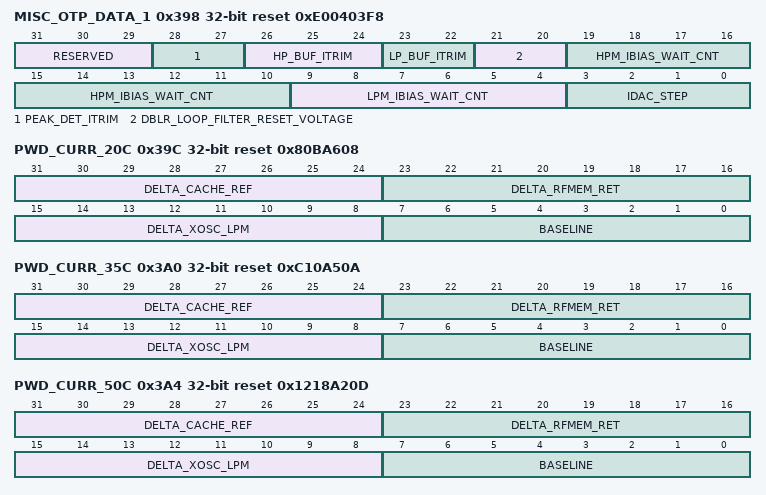
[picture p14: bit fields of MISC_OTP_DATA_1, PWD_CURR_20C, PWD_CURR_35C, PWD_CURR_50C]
0x398 MISC_OTP_DATA_1 reset 0xE00403F8 — Internal. Only to be used through TI provided API.
  [31:29] RESERVED ro — [31:29] Internal. Only to be used through TI provided API.
  [28:27] PEAK_DET_ITRIM ro — [28:27] Internal. Only to be used through TI provided API.
  [26:24] HP_BUF_ITRIM ro — [26:24] Internal. Only to be used through TI provided API.
  [23:22] LP_BUF_ITRIM ro — [23:22] Internal. Only to be used through TI provided API.
  [21:20] DBLR_LOOP_FILTER_RESET_VOLTAGE ro — [21:20] Internal. Only to be used through TI provided API.
  [19:10] HPM_IBIAS_WAIT_CNT ro — [19:10] Internal. Only to be used through TI provided API.
  [9:4] LPM_IBIAS_WAIT_CNT ro — [9:4] Internal. Only to be used through TI provided API.
  [3:0] IDAC_STEP ro — [3:0] Internal. Only to be used through TI provided API.
0x39C PWD_CURR_20C reset 0x80BA608 — Power Down Current Control 20C
  [31:24] DELTA_CACHE_REF ro — [31:24] Additional maximum current, in units of 1uA, with cache retention
  [23:16] DELTA_RFMEM_RET ro — [23:16] Additional maximum current, in 1uA units, with RF memory retention
  [15:8] DELTA_XOSC_LPM ro — [15:8] Additional maximum current, in units of 1uA, with XOSC_HF on in low-power mode
  [7:0] BASELINE ro — [7:0] Worst-case baseline maximum powerdown current, in units of 0.5uA
0x3A0 PWD_CURR_35C reset 0xC10A50A — Power Down Current Control 35C
  fields as PWD_CURR_20C
0x3A4 PWD_CURR_50C reset 0x1218A20D — Power Down Current Control 50C
  fields as PWD_CURR_20C
0x3A8 PWD_CURR_65C reset 0x1C259C14 — Power Down Current Control 65C
  fields as PWD_CURR_20C
0x3AC PWD_CURR_80C reset 0x2E3B9021 — Power Down Current Control 80C
  fields as PWD_CURR_20C
0x3B0 PWD_CURR_95C reset 0x4C627A3B — Power Down Current Control 95C
  fields as PWD_CURR_20C
0x3B4 PWD_CURR_110C reset 0x789E706B — Power Down Current Control 110C
  fields as PWD_CURR_20C
0x3B8 PWD_CURR_125C reset 0xADE1809A — Power Down Current Control 125C
  fields as PWD_CURR_20C
